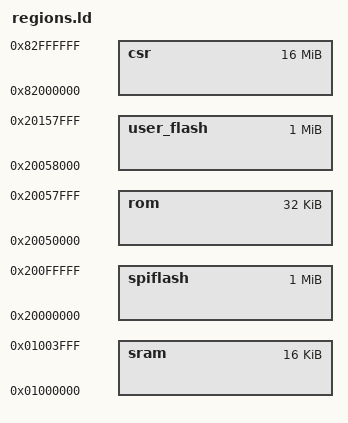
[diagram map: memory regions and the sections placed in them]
MEMORY {
	sram : ORIGIN = 0x01000000, LENGTH = 0x00004000
	csr : ORIGIN = 0x82000000, LENGTH = 0x01000000
	spiflash : ORIGIN = 0x20000000, LENGTH = 0x00100000
	rom : ORIGIN = 0x20050000, LENGTH = 0x00008000
	user_flash : ORIGIN = 0x20058000, LENGTH = 0x00100000
}
